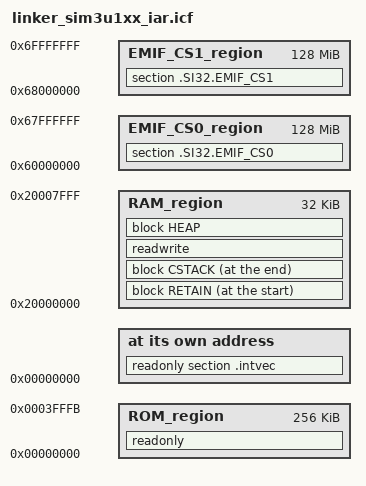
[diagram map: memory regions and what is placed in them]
/*###ICF### Section handled by ICF editor, don't touch! ****/
/*-Editor annotation file-*/
/* IcfEditorFile="$TOOLKIT_DIR$\config\ide\IcfEditor\cortex_v1_0.xml" */
/*-Specials-*/
define symbol __ICFEDIT_intvec_start__ = 0x00000000;
/*-Memory Regions-*/
define symbol __ICFEDIT_region_ROM_start__   = 0x00000000;
define symbol __ICFEDIT_region_ROM_end__     = 0x0003FFFB;
define symbol __ICFEDIT_region_RAM_start__   = 0x20000000;
define symbol __ICFEDIT_region_RAM_end__     = 0x20007FFF;
/*-Sizes-*/
define symbol __ICFEDIT_size_cstack__   = 0x400;
define symbol __ICFEDIT_size_heap__     = 0x800;
/**** End of ICF editor section. ###ICF###*/


/* IAR Linker Configuration File for SiM3U1xx Device Family */

define symbol SI32_MCU_RETENTION_RAM_SIZE = 4K;
define symbol SI32_MCU_EMIF_BASE = 0x60000000;
define symbol SI32_MCU_EMIF_SIZE = 128M;

define memory mem with size = 4G;

define region ROM_region = mem:[from __ICFEDIT_region_ROM_start__ to __ICFEDIT_region_ROM_end__];
define region RAM_region = mem:[from __ICFEDIT_region_RAM_start__ to __ICFEDIT_region_RAM_end__];
define region EMIF_CS0_region = mem:[from SI32_MCU_EMIF_BASE size SI32_MCU_EMIF_SIZE];
define region EMIF_CS1_region = mem:[from SI32_MCU_EMIF_BASE+SI32_MCU_EMIF_SIZE size SI32_MCU_EMIF_SIZE];

define block RETAIN with maximum size = SI32_MCU_RETENTION_RAM_SIZE { zi section .SI32.RETENTION };
define block CSTACK with alignment = 8, size = __ICFEDIT_size_cstack__ { };
define block HEAP   with alignment = 8, size = __ICFEDIT_size_heap__   { };

initialize by copy  { readwrite };
//initialize by copy with packing = none { section __DLIB_PERTHREAD }; // Required in a multi-threaded application
do not initialize   { section .noinit, zi section .SI32.RETENTION };

place at address mem:__ICFEDIT_intvec_start__ { readonly section .intvec };

place in ROM_region { readonly };

place at start of RAM_region { block RETAIN };
place at end of RAM_region   { block CSTACK };
place in RAM_region { readwrite, block HEAP };

place in EMIF_CS0_region { section .SI32.EMIF_CS0 };
place in EMIF_CS1_region { section .SI32.EMIF_CS1 };
